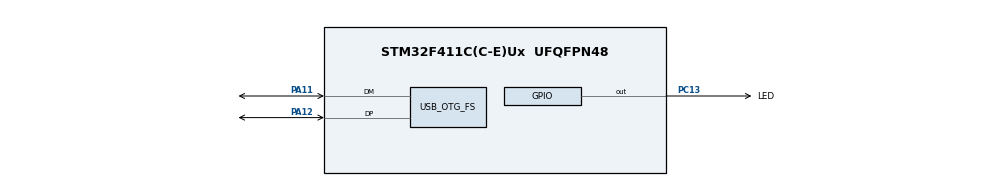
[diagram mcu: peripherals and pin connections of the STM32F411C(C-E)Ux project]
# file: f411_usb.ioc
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FREERTOS.INCLUDE_eTaskGetState=1
FREERTOS.INCLUDE_pcTaskGetTaskName=1
FREERTOS.INCLUDE_uxTaskGetStackHighWaterMark=1
FREERTOS.INCLUDE_vTaskDelayUntil=1
FREERTOS.INCLUDE_xEventGroupSetBitFromISR=0
FREERTOS.INCLUDE_xTaskAbortDelay=1
FREERTOS.INCLUDE_xTaskGetCurrentTaskHandle=1
FREERTOS.INCLUDE_xTaskGetHandle=1
FREERTOS.INCLUDE_xTimerPendFunctionCall=1
FREERTOS.Tasks01=app_start,0,256,AppTaskStart,As weak,NULL,Dynamic,NULL,NULL
FREERTOS.configCHECK_FOR_STACK_OVERFLOW=2
FREERTOS.configENABLE_FPU=1
FREERTOS.configGENERATE_RUN_TIME_STATS=1
FREERTOS.configTIMER_TASK_STACK_DEPTH=128
FREERTOS.configTOTAL_HEAP_SIZE=16384
FREERTOS.configUSE_COUNTING_SEMAPHORES=1
FREERTOS.configUSE_IDLE_HOOK=0
FREERTOS.configUSE_RECURSIVE_MUTEXES=1
FREERTOS.configUSE_STATS_FORMATTING_FUNCTIONS=1
FREERTOS.configUSE_TICKLESS_IDLE=0
FREERTOS.configUSE_TIMERS=1
FREERTOS.configUSE_TRACE_FACILITY=1
Mcu.Family=STM32F4
Mcu.Name=STM32F411C(C-E)Ux
Mcu.Package=UFQFPN48
NVIC.OTG_FS_IRQn=true\:5\:0\:false\:false\:true\:true\:true\:true\:true
NVIC.PriorityGroup=NVIC_PRIORITYGROUP_4
NVIC.TIM1_TRG_COM_TIM11_IRQn=true\:15\:0\:false\:false\:true\:false\:false\:true\:true
NVIC.TIM1_UP_TIM10_IRQn=true\:5\:0\:false\:false\:true\:true\:true\:true\:true
NVIC.TimeBase=TIM1_TRG_COM_TIM11_IRQn
NVIC.TimeBaseIP=TIM11
PA11.Mode=Device_Only
PA11.Signal=USB_OTG_FS_DM
PA12.Mode=Device_Only
PA12.Signal=USB_OTG_FS_DP
PA13.Mode=Serial_Wire
PA13.Signal=SYS_JTMS-SWDIO
PA14.Mode=Serial_Wire
PA14.Signal=SYS_JTCK-SWCLK
PC13-ANTI_TAMP.GPIO_Label=LED
PC13-ANTI_TAMP.GPIO_PuPd=GPIO_PULLDOWN
PC13-ANTI_TAMP.GPIO_Speed=GPIO_SPEED_FREQ_LOW
PC13-ANTI_TAMP.PinState=GPIO_PIN_SET
PC13-ANTI_TAMP.Signal=GPIO_Output
PH0\ -\ OSC_IN.Mode=HSE-External-Oscillator
PH0\ -\ OSC_IN.Signal=RCC_OSC_IN
PH1\ -\ OSC_OUT.Mode=HSE-External-Oscillator
PH1\ -\ OSC_OUT.Signal=RCC_OSC_OUT
ProjectManager.HeapSize=0x400
ProjectManager.StackSize=0x1000
ProjectManager.TargetToolchain=CMake
RCC.48MHZClocksFreq_Value=48000000
RCC.AHBFreq_Value=96000000
RCC.APB1CLKDivider=RCC_HCLK_DIV2
RCC.APB1Freq_Value=48000000
RCC.APB1TimFreq_Value=96000000
RCC.APB2Freq_Value=96000000
RCC.APB2TimFreq_Value=96000000
RCC.CortexFreq_Value=96000000
RCC.HCLKFreq_Value=96000000
RCC.HSE_VALUE=25000000
RCC.HSI_VALUE=16000000
RCC.LSE_VALUE=32768
RCC.PLLM=25
RCC.SYSCLKFreq_VALUE=96000000
RCC.SYSCLKSource=RCC_SYSCLKSOURCE_PLLCLK
RCC.VCOOutputFreq_Value=192000000
TIM10.AutoReloadPreload=TIM_AUTORELOAD_PRELOAD_ENABLE
TIM10.Period=99
TIM10.Prescaler=95
USB_OTG_FS.VirtualMode=Device_Only
VP_FREERTOS_VS_CMSIS_V1.Mode=CMSIS_V1
VP_SYS_VS_tim11.Mode=TIM11
VP_TIM10_VS_ClockSourceINT.Mode=Enable_Timer
board=custom

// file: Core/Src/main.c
/* USER CODE BEGIN Header */
/**
  ******************************************************************************
  * @file           : main.c
  * @brief          : Main program body
  ******************************************************************************
  * @attention
  *
  * Copyright (c) 2025 STMicroelectronics.
  * All rights reserved.
  *
  * This software is licensed under terms that can be found in the LICENSE file
  * in the root directory of this software component.
  * If no LICENSE file comes with this software, it is provided AS-IS.
  *
  ******************************************************************************
  */
/* USER CODE END Header */
#include "main.h"
#include "cmsis_os.h"
#include "tim.h"
#include "usb_otg.h"
#include "gpio.h"

/* USER CODE BEGIN Includes */
#include "SEGGER_RTT.h"
/* USER CODE END Includes */

void SystemClock_Config(void);
void MX_FREERTOS_Init(void);

int main(void)
{

  /* MCU Configuration--------------------------------------------------------*/

  /* Reset of all peripherals, Initializes the Flash interface and the Systick. */
  HAL_Init();

  /* Configure the system clock */
  SystemClock_Config();

  /* USER CODE BEGIN SysInit */
  SEGGER_RTT_Init();
  /* USER CODE END SysInit */

  /* Initialize all configured peripherals */
  MX_GPIO_Init();
  MX_USB_OTG_FS_PCD_Init();
  MX_TIM10_Init();

  /* Call init function for freertos objects (in cmsis_os2.c) */
  MX_FREERTOS_Init();

  /* Start scheduler */
  osKernelStart();

  /* We should never get here as control is now taken by the scheduler */

  /* Infinite loop */
  while (1)
  {

  }
}

void SystemClock_Config(void)
{
  LL_FLASH_SetLatency(LL_FLASH_LATENCY_3);
  while(LL_FLASH_GetLatency()!= LL_FLASH_LATENCY_3)
  {
  }
  LL_PWR_SetRegulVoltageScaling(LL_PWR_REGU_VOLTAGE_SCALE1);
  LL_RCC_HSE_Enable();

   /* Wait till HSE is ready */
  while(LL_RCC_HSE_IsReady() != 1)
  {

  }
  LL_RCC_PLL_ConfigDomain_SYS(LL_RCC_PLLSOURCE_HSE, LL_RCC_PLLM_DIV_25, 192, LL_RCC_PLLP_DIV_2);
  LL_RCC_PLL_ConfigDomain_48M(LL_RCC_PLLSOURCE_HSE, LL_RCC_PLLM_DIV_25, 192, LL_RCC_PLLQ_DIV_4);
  LL_RCC_PLL_Enable();

   /* Wait till PLL is ready */
  while(LL_RCC_PLL_IsReady() != 1)
  {

  }
  while (LL_PWR_IsActiveFlag_VOS() == 0)
  {
  }
  LL_RCC_SetAHBPrescaler(LL_RCC_SYSCLK_DIV_1);
  LL_RCC_SetAPB1Prescaler(LL_RCC_APB1_DIV_2);
  LL_RCC_SetAPB2Prescaler(LL_RCC_APB2_DIV_1);
  LL_RCC_SetSysClkSource(LL_RCC_SYS_CLKSOURCE_PLL);

   /* Wait till System clock is ready */
  while(LL_RCC_GetSysClkSource() != LL_RCC_SYS_CLKSOURCE_STATUS_PLL)
  {

  }
  LL_SetSystemCoreClock(96000000);

   /* Update the time base */
  if (HAL_InitTick (TICK_INT_PRIORITY) != HAL_OK)
  {
    Error_Handler();
  }
  LL_RCC_SetTIMPrescaler(LL_RCC_TIM_PRESCALER_TWICE);
}

void HAL_TIM_PeriodElapsedCallback(TIM_HandleTypeDef *htim)
{
  if (htim->Instance == TIM11)
  {
    HAL_IncTick();
  }
}

void Error_Handler(void)
{
  __disable_irq();
  while (1)
  {
  }
}

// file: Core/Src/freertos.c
/* USER CODE BEGIN Header */
/**
  ******************************************************************************
  * File Name          : freertos.c
  * Description        : Code for freertos applications
  ******************************************************************************
  * @attention
  *
  * Copyright (c) 2025 STMicroelectronics.
  * All rights reserved.
  *
  * This software is licensed under terms that can be found in the LICENSE file
  * in the root directory of this software component.
  * If no LICENSE file comes with this software, it is provided AS-IS.
  *
  ******************************************************************************
  */
/* USER CODE END Header */

#include "FreeRTOS.h"
#include "task.h"
#include "main.h"
#include "cmsis_os.h"

/* USER CODE BEGIN Includes */
#include <stdio.h>

#include "SEGGER_RTT.h"
#include "xcmd.h"
/* USER CODE END Includes */

osThreadId app_startHandle;

void AppTaskStart(void const * argument);

void MX_FREERTOS_Init(void); /* (MISRA C 2004 rule 8.1) */

/* GetIdleTaskMemory prototype (linked to static allocation support) */
void vApplicationGetIdleTaskMemory( StaticTask_t **ppxIdleTaskTCBBuffer, StackType_t **ppxIdleTaskStackBuffer, uint32_t *pulIdleTaskStackSize );

/* GetTimerTaskMemory prototype (linked to static allocation support) */
void vApplicationGetTimerTaskMemory( StaticTask_t **ppxTimerTaskTCBBuffer, StackType_t **ppxTimerTaskStackBuffer, uint32_t *pulTimerTaskStackSize );

/* Hook prototypes */
void configureTimerForRunTimeStats(void);
unsigned long getRunTimeCounterValue(void);
void vApplicationStackOverflowHook(xTaskHandle xTask, signed char *pcTaskName);

/* USER CODE BEGIN 1 */
volatile static unsigned long tim_cnt = 0;

void tim_cnt_incrense(void) {
  tim_cnt++;
}

/* Functions needed when configGENERATE_RUN_TIME_STATS is on */
__weak void configureTimerForRunTimeStats(void)
{
  tim_cnt = 0;
}

__weak unsigned long getRunTimeCounterValue(void)
{
  return tim_cnt;
}

void RecordErrorInformationHere(const char *const pcFile, int ulLine) {
    printf("FreeRTOS Kernel Fault: %s, %d Assertion Fail!\r\n", pcFile, ulLine);
    __asm__ volatile("cpsid if");
    __asm__ volatile("b .");
}

void vAssertCalled(const char *pcFile, int ulLine) {
    RecordErrorInformationHere(pcFile, ulLine);
    /* Disable interrupts so the tick interrupt stops executing, then sit in a loop
     * so execution does not move past the line that failed the assertion. */
    taskDISABLE_INTERRUPTS();
    for (;;);
}
/* USER CODE END 1 */

/* USER CODE BEGIN 4 */
__weak void vApplicationStackOverflowHook(xTaskHandle xTask, signed char *pcTaskName)
{
   /* Run time stack overflow checking is performed if
   configCHECK_FOR_STACK_OVERFLOW is defined to 1 or 2. This hook function is
   called if a stack overflow is detected. */
   printf("FreeRTOS Kernel Fault:%20s Task StackOverFlow!\r\n", pcTaskName);
}
/* USER CODE END 4 */

/* USER CODE BEGIN GET_IDLE_TASK_MEMORY */
static StaticTask_t xIdleTaskTCBBuffer;
static StackType_t xIdleStack[configMINIMAL_STACK_SIZE];

void vApplicationGetIdleTaskMemory( StaticTask_t **ppxIdleTaskTCBBuffer, StackType_t **ppxIdleTaskStackBuffer, uint32_t *pulIdleTaskStackSize )
{
  *ppxIdleTaskTCBBuffer = &xIdleTaskTCBBuffer;
  *ppxIdleTaskStackBuffer = &xIdleStack[0];
  *pulIdleTaskStackSize = configMINIMAL_STACK_SIZE;
  /* place for user code */
}
/* USER CODE END GET_IDLE_TASK_MEMORY */

/* USER CODE BEGIN GET_TIMER_TASK_MEMORY */
static StaticTask_t xTimerTaskTCBBuffer;
static StackType_t xTimerStack[configTIMER_TASK_STACK_DEPTH];

void vApplicationGetTimerTaskMemory( StaticTask_t **ppxTimerTaskTCBBuffer, StackType_t **ppxTimerTaskStackBuffer, uint32_t *pulTimerTaskStackSize )
{
  *ppxTimerTaskTCBBuffer = &xTimerTaskTCBBuffer;
  *ppxTimerTaskStackBuffer = &xTimerStack[0];
  *pulTimerTaskStackSize = configTIMER_TASK_STACK_DEPTH;
  /* place for user code */
}
/* USER CODE END GET_TIMER_TASK_MEMORY */

void MX_FREERTOS_Init(void) {

  /* Create the thread(s) */
  /* definition and creation of app_start */
  osThreadDef(app_start, AppTaskStart, osPriorityNormal, 0, 256);
  app_startHandle = osThreadCreate(osThread(app_start), NULL);

}

/* USER CODE BEGIN Header_AppTaskStart */
#define ARRAY_SIZE(array_name) ((int)(sizeof(array_name) / sizeof(array_name[0])))

static void xcmd_entry(void *arg);

static struct TaskInit_t {
  TaskFunction_t pxTaskCode;
  const char *const pcName;
  const configSTACK_DEPTH_TYPE uxStackDepth;
  void *const pvParameters;
  UBaseType_t uxPriority;
} xTaskInitTable[] = {
  {xcmd_entry, "shell", 512, NULL, 6},
};
static TaskHandle_t xTaskHandles[ARRAY_SIZE(xTaskInitTable)];

/**
  * @brief  Function implementing the app_start thread.
  * @param  argument: Not used
  * @retval None
  */
/* USER CODE END Header_AppTaskStart */
__weak void AppTaskStart(void const * argument)
{
  /* USER CODE BEGIN AppTaskStart */
  BaseType_t ret;

  for (size_t i = 0; i < ARRAY_SIZE(xTaskInitTable); ++i) {
    ret = xTaskCreate(xTaskInitTable[i].pxTaskCode,
                      xTaskInitTable[i].pcName,
                      xTaskInitTable[i].uxStackDepth,
                      xTaskInitTable[i].pvParameters,
                      xTaskInitTable[i].uxPriority,
                      &xTaskHandles[i]);
    if (pdPASS != ret) {
        printf("\r\nTask \"%s\" failed to be created! (%ld)\r\n", xTaskInitTable[i].pcName, ret);
        Error_Handler();
    }
  }

  for (;;) {
    LL_GPIO_TogglePin(LED_GPIO_Port, LED_Pin);
    osDelay(500);
  }
  /* USER CODE END AppTaskStart */
}

/* USER CODE BEGIN Application */
void taskYieldToAll(void) {
  UBaseType_t uxSaved = uxTaskPriorityGet(NULL);
  vTaskPrioritySet(NULL, tskIDLE_PRIORITY);  // 降到 0
  /* 此时调度器立刻选下一个最高就绪任务 */
  vTaskPrioritySet(NULL, uxSaved);  // 再升回来
}

int cmd_get_char(uint8_t *ch) {
  return (1 == SEGGER_RTT_Read(0, ch, 1));
}

int cmd_put_char(uint8_t ch) {
  return SEGGER_RTT_PutChar(0, ch);
}

static void xcmd_entry(void *arg) {
  xcmd_init(cmd_get_char, cmd_put_char);

  for (;;) {
    xcmd_task();
    taskYieldToAll();
  }
}

/*
 * Macros used by vListTask to indicate which state a task is in.
 */
#define tskRUNNING_CHAR ('X')
#define tskBLOCKED_CHAR ('B')
#define tskREADY_CHAR ('R')
#define tskDELETED_CHAR ('D')
#define tskSUSPENDED_CHAR ('S')

int cmd_ps(int argc, char **argv) {
  char pxWriteBuffer[256];
  TaskStatus_t *pxTaskStatusArray;
  volatile UBaseType_t uxArraySize, x;
  uint32_t ulTotalRunTime, ulStatsAsPercentage;
  char cStatus;

  /* Take a snapshot of the number of tasks in case it changes while this
      function is executing. */
  uxArraySize = uxTaskGetNumberOfTasks();

  /* Allocate a TaskStatus_t structure for each task. An array could be
      allocated statically at compile time. */
  pxTaskStatusArray = pvPortMalloc(uxArraySize * sizeof(TaskStatus_t));

  if (pxTaskStatusArray != NULL) {
    snprintf(pxWriteBuffer, sizeof(pxWriteBuffer),
              "%-*s %-*s %-*s %-*s %-*s %-*s %s\r\n",
              16, "thread",
              8, "status",
              8, "prio",
              8, "remain",
              8, "id",
              16, "tick",
              "used");
    printf("%s", pxWriteBuffer);
    snprintf(pxWriteBuffer, sizeof(pxWriteBuffer),
              "%-*s %-*s %-*s %-*s %-*s %-*s %s\r\n",
              16, "----------------",
              8, "--------",
              8, "--------",
              8, "--------",
              8, "--------",
              16, "----------------",
              "-----");
    printf("%s", pxWriteBuffer);

    /* Generate raw status information about each task. */
    uxArraySize = uxTaskGetSystemState(pxTaskStatusArray, uxArraySize, &ulTotalRunTime);

    /* For percentage calculations. */
    ulTotalRunTime /= 100UL;

    /* Avoid divide by zero errors. */
    if (ulTotalRunTime > 0) {
      /* For each populated position in the pxTaskStatusArray array,
          format the raw data as human readable ASCII data. */
      for (x = 0; x < uxArraySize; x++) {
        switch (pxTaskStatusArray[x].eCurrentState) {
          case eRunning:
            cStatus = tskRUNNING_CHAR;
            break;

          case eReady:
            cStatus = tskREADY_CHAR;
            break;

          case eBlocked:
            cStatus = tskBLOCKED_CHAR;
            break;

          case eSuspended:
            cStatus = tskSUSPENDED_CHAR;
            break;

          case eDeleted:
            cStatus = tskDELETED_CHAR;
            break;

          case eInvalid: /* Fall through. */
          default:       /* Should not get here, but it is included
                          * to prevent static checking errors. */
            cStatus = (char)0x00;
            break;
        }

        /* What percentage of the total run time has the task used?
            This will always be rounded down to the nearest integer.
            ulTotalRunTimeDiv100 has already been divided by 100. */
        ulStatsAsPercentage = pxTaskStatusArray[x].ulRunTimeCounter / ulTotalRunTime;

        if (ulStatsAsPercentage > 0UL) {
          snprintf(pxWriteBuffer, sizeof(pxWriteBuffer),
                    "%-*s %-*c %-*u %-*u %-*u %-*lu %lu%%\r\n",
                    16, pxTaskStatusArray[x].pcTaskName,
                    8, cStatus,
                    8, (unsigned int)pxTaskStatusArray[x].uxCurrentPriority,
                    8, (unsigned int)pxTaskStatusArray[x].usStackHighWaterMark,
                    8, (unsigned int)pxTaskStatusArray[x].xTaskNumber,
                    16, pxTaskStatusArray[x].ulRunTimeCounter,
                    ulStatsAsPercentage);
          printf("%s", pxWriteBuffer);
        } else {
          /* If the percentage is zero here then the task has
              consumed less than 1% of the total run time. */
          snprintf(pxWriteBuffer, sizeof(pxWriteBuffer),
                    "%-*s %-*c %-*u %-*u %-*u %-*lu %s\r\n",
                    16, pxTaskStatusArray[x].pcTaskName,
                    8, cStatus,
                    8, (unsigned int)pxTaskStatusArray[x].uxCurrentPriority,
                    8, (unsigned int)pxTaskStatusArray[x].usStackHighWaterMark,
                    8, (unsigned int)pxTaskStatusArray[x].xTaskNumber,
                    16, pxTaskStatusArray[x].ulRunTimeCounter,
                    "<1%");
          printf("%s", pxWriteBuffer);
        }
      }
    }

    /* The array is no longer needed, free the memory it consumes. */
    vPortFree(pxTaskStatusArray);
  }

  snprintf(pxWriteBuffer, sizeof(pxWriteBuffer), ">>-------------------  free heap memory: %6d bytes  -------------------<<\r\n", xPortGetFreeHeapSize());
  printf("%s", pxWriteBuffer);

  return 0;
}
XCMD_EXPORT_CMD(ps, cmd_ps, "list task info");

int cmd_hardfault(int argc, char **argv) {
  /* Cause a hardfault */
  volatile uint32_t *invalidPtr = (uint32_t*)0xCCCCCCCC;
  volatile uint32_t notGonnaHappen = *invalidPtr;
  return notGonnaHappen;
}
XCMD_EXPORT_CMD(hardfault, cmd_hardfault, "Cause a hardfault");
/* USER CODE END Application */
